AUTOSAR XML (schema 00046)
package /ComponentTypes
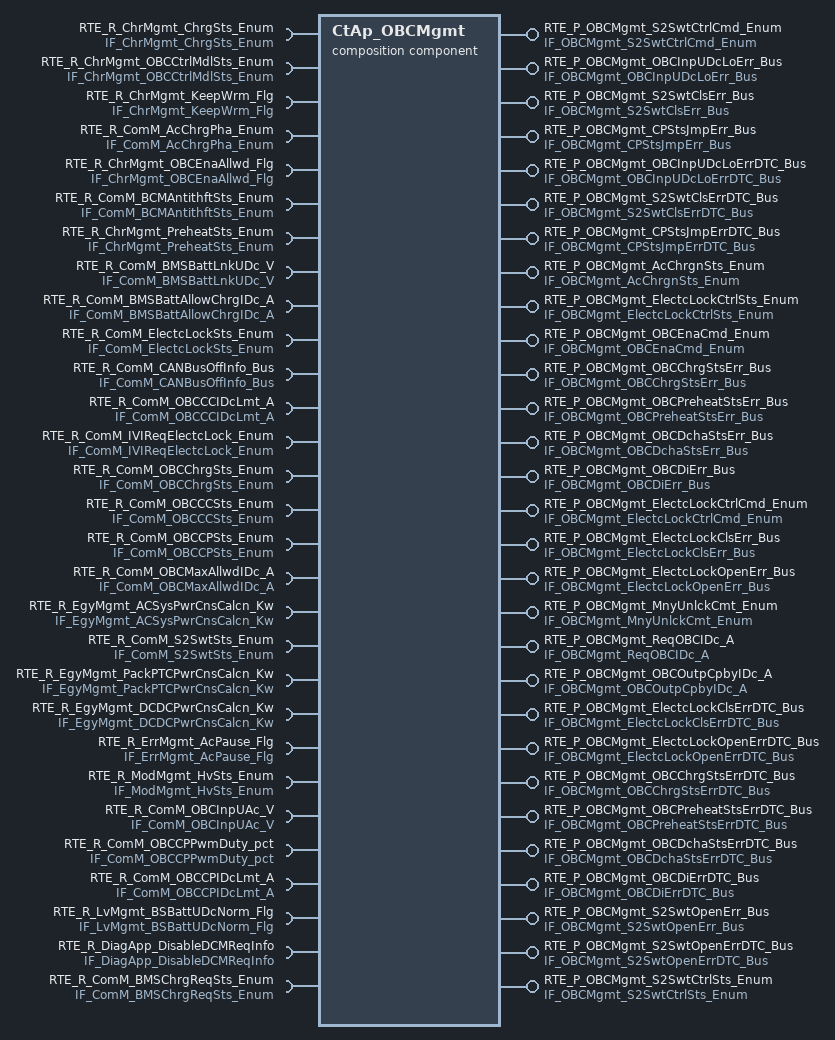
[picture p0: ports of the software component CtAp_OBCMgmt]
  composition sw component type CtAp_OBCMgmt
    26 x provide port:
      RTE_P_OBCMgmt_S2SwtCtrlCmd_Enum: nonqueued-sender-com-spec{data-element=tec_OBCMgmt_S2SwtCtrlCmd_Enum, init-value=0}, provided-interface=IF_OBCMgmt_S2SwtCtrlCmd_Enum
      RTE_P_OBCMgmt_OBCInpUDcLoErr_Bus: nonqueued-sender-com-spec{data-element=tec_OBCMgmt_OBCInpUDcLoErr_Bus, init-value=fields=[OBCMgmt_MonStatOBCInpUDcLoErr:0, OBCMgmt_MonResOBCInpUDcLoErr:0, OBCMgmt_ErrStatOBCInpUDcLoErr:0, OBCMgmt_ErrResOBCInpUDcLoErr:0]}, provided-interface=IF_OBCMgmt_OBCInpUDcLoErr_Bus
      RTE_P_OBCMgmt_S2SwtClsErr_Bus: nonqueued-sender-com-spec{data-element=tec_OBCMgmt_S2SwtClsErr_Bus, init-value=fields=[OBCMgmt_MonStatS2SwtClsErr:0, OBCMgmt_MonResS2SwtClsErr:0, OBCMgmt_ErrStatS2SwtClsErr:0, OBCMgmt_ErrResS2SwtClsErr:0]}, provided-interface=IF_OBCMgmt_S2SwtClsErr_Bus
      RTE_P_OBCMgmt_CPStsJmpErr_Bus: nonqueued-sender-com-spec{data-element=tec_OBCMgmt_CPStsJmpErr_Bus, init-value=fields=[OBCMgmt_MonStatCPStsJmpErr:0, OBCMgmt_MonResCPStsJmpErr:0, OBCMgmt_ErrStatCPStsJmpErr:0, OBCMgmt_ErrResCPStsJmpErr:0]}, provided-interface=IF_OBCMgmt_CPStsJmpErr_Bus
      RTE_P_OBCMgmt_OBCInpUDcLoErrDTC_Bus: nonqueued-sender-com-spec{data-element=tec_OBCMgmt_OBCInpUDcLoErrDTC_Bus, init-value=fields=[OBCMgmt_MonStatOBCInpUDcLoErrDTC:0, OBCMgmt_MonResOBCInpUDcLoErrDTC:0, OBCMgmt_ErrStatOBCInpUDcLoErrDTC:0, OBCMgmt_ErrResOBCInpUDcLoErrDTC:0]}, provided-interface=IF_OBCMgmt_OBCInpUDcLoErrDTC_Bus
      RTE_P_OBCMgmt_S2SwtClsErrDTC_Bus: nonqueued-sender-com-spec{data-element=tec_OBCMgmt_S2SwtClsErrDTC_Bus, init-value=fields=[OBCMgmt_MonStatS2SwtClsErrDTC:0, OBCMgmt_MonResS2SwtClsErrDTC:0, OBCMgmt_ErrStatS2SwtClsErrDTC:0, OBCMgmt_ErrResS2SwtClsErrDTC:0]}, provided-interface=IF_OBCMgmt_S2SwtClsErrDTC_Bus
      RTE_P_OBCMgmt_CPStsJmpErrDTC_Bus: nonqueued-sender-com-spec{data-element=tec_OBCMgmt_CPStsJmpErrDTC_Bus, init-value=fields=[OBCMgmt_MonStatCPStsJmpErrDTC:0, OBCMgmt_MonResCPStsJmpErrDTC:0, OBCMgmt_ErrStatCPStsJmpErrDTC:0, OBCMgmt_ErrResCPStsJmpErrDTC:0]}, provided-interface=IF_OBCMgmt_CPStsJmpErrDTC_Bus
      RTE_P_OBCMgmt_AcChrgnSts_Enum: nonqueued-sender-com-spec{data-element=tec_OBCMgmt_AcChrgnSts_Enum, init-value=0}, provided-interface=IF_OBCMgmt_AcChrgnSts_Enum
      RTE_P_OBCMgmt_ElectcLockCtrlSts_Enum: nonqueued-sender-com-spec{data-element=tec_OBCMgmt_ElectcLockCtrlSts_Enum, init-value=0}, provided-interface=IF_OBCMgmt_ElectcLockCtrlSts_Enum
      RTE_P_OBCMgmt_OBCEnaCmd_Enum: nonqueued-sender-com-spec{data-element=tec_OBCMgmt_OBCEnaCmd_Enum, init-value=0}, provided-interface=IF_OBCMgmt_OBCEnaCmd_Enum
      RTE_P_OBCMgmt_OBCChrgStsErr_Bus: nonqueued-sender-com-spec{data-element=tec_OBCMgmt_OBCChrgStsErr_Bus, init-value=fields=[OBCMgmt_MonStatOBCChrgStsErr:0, OBCMgmt_MonResOBCChrgStsErr:0, OBCMgmt_ErrStatOBCChrgStsErr:0, OBCMgmt_ErrResOBCChrgStsErr:0]}, provided-interface=IF_OBCMgmt_OBCChrgStsErr_Bus
      RTE_P_OBCMgmt_OBCPreheatStsErr_Bus: nonqueued-sender-com-spec{data-element=tec_OBCMgmt_OBCPreheatStsErr_Bus, init-value=fields=[OBCMgmt_MonStatOBCPreheatStsErr:0, OBCMgmt_MonResOBCPreheatStsErr:0, OBCMgmt_ErrStatOBCPreheatStsErr:0, OBCMgmt_ErrResOBCPreheatStsErr:0]}, provided-interface=IF_OBCMgmt_OBCPreheatStsErr_Bus
      RTE_P_OBCMgmt_OBCDchaStsErr_Bus: nonqueued-sender-com-spec{data-element=tec_OBCMgmt_OBCDchaStsErr_Bus, init-value=fields=[OBCMgmt_MonStatOBCDchaStsErr:0, OBCMgmt_MonResOBCDchaStsErr:0, OBCMgmt_ErrStatOBCDchaStsErr:0, OBCMgmt_ErrResOBCDchaStsErr:0]}, provided-interface=IF_OBCMgmt_OBCDchaStsErr_Bus
      RTE_P_OBCMgmt_OBCDiErr_Bus: nonqueued-sender-com-spec{data-element=tec_OBCMgmt_OBCDiErr_Bus, init-value=fields=[OBCMgmt_MonStatOBCDiErr:0, OBCMgmt_MonResOBCDiErr:0, OBCMgmt_ErrStatOBCDiErr:0, OBCMgmt_ErrResOBCDiErr:0]}, provided-interface=IF_OBCMgmt_OBCDiErr_Bus
      RTE_P_OBCMgmt_ElectcLockCtrlCmd_Enum: nonqueued-sender-com-spec{data-element=tec_OBCMgmt_ElectcLockCtrlCmd_Enum, init-value=0}, provided-interface=IF_OBCMgmt_ElectcLockCtrlCmd_Enum
      RTE_P_OBCMgmt_ElectcLockClsErr_Bus: nonqueued-sender-com-spec{data-element=tec_OBCMgmt_ElectcLockClsErr_Bus, init-value=fields=[OBCMgmt_MonStatElectcLockClsErr:0, OBCMgmt_MonResElectcLockClsErr:0, OBCMgmt_ErrStatElectcLockClsErr:0, OBCMgmt_ErrResElectcLockClsErr:0]}, provided-interface=IF_OBCMgmt_ElectcLockClsErr_Bus
      RTE_P_OBCMgmt_ElectcLockOpenErr_Bus: nonqueued-sender-com-spec{data-element=tec_OBCMgmt_ElectcLockOpenErr_Bus, init-value=fields=[OBCMgmt_MonStatElectcLockOpenErr:0, OBCMgmt_MonResElectcLockOpenErr:0, OBCMgmt_ErrStatElectcLockOpenErr:0, OBCMgmt_ErrResElectcLockOpenErr:0]}, provided-interface=IF_OBCMgmt_ElectcLockOpenErr_Bus
      RTE_P_OBCMgmt_MnyUnlckCmt_Enum: nonqueued-sender-com-spec{data-element=tec_OBCMgmt_MnyUnlckCmt_Enum, init-value=0}, provided-interface=IF_OBCMgmt_MnyUnlckCmt_Enum
      RTE_P_OBCMgmt_ReqOBCIDc_A: nonqueued-sender-com-spec{data-element=tec_OBCMgmt_ReqOBCIDc_A, init-value=0}, provided-interface=IF_OBCMgmt_ReqOBCIDc_A
      RTE_P_OBCMgmt_OBCOutpCpbyIDc_A: nonqueued-sender-com-spec{data-element=tec_OBCMgmt_OBCOutpCpbyIDc_A, init-value=0}, provided-interface=IF_OBCMgmt_OBCOutpCpbyIDc_A
      RTE_P_OBCMgmt_ElectcLockClsErrDTC_Bus: nonqueued-sender-com-spec{data-element=tec_OBCMgmt_ElectcLockClsErrDTC_Bus, init-value=fields=[OBCMgmt_MonStatElectcLockClsErrDTC:0, OBCMgmt_MonResElectcLockClsErrDTC:0, OBCMgmt_ErrStatElectcLockClsErrDTC:0, OBCMgmt_ErrResElectcLockClsErrDTC:0]}, provided-interface=IF_OBCMgmt_ElectcLockClsErrDTC_Bus
      RTE_P_OBCMgmt_ElectcLockOpenErrDTC_Bus: nonqueued-sender-com-spec{data-element=tec_OBCMgmt_ElectcLockOpenErrDTC_Bus, init-value=fields=[OBCMgmt_MonStatElectcLockOpenErrDTC:0, OBCMgmt_MonResElectcLockOpenErrDTC:0, OBCMgmt_ErrStatElectcLockOpenErrDTC:0, OBCMgmt_ErrResElectcLockOpenErrDTC:0]}, provided-interface=IF_OBCMgmt_ElectcLockOpenErrDTC_Bus
      RTE_P_OBCMgmt_OBCChrgStsErrDTC_Bus: nonqueued-sender-com-spec{data-element=tec_OBCMgmt_OBCChrgStsErrDTC_Bus, init-value=fields=[OBCMgmt_MonStatOBCChrgStsErrDTC:0, OBCMgmt_MonResOBCChrgStsErrDTC:0, OBCMgmt_ErrStatOBCChrgStsErrDTC:0, OBCMgmt_ErrResOBCChrgStsErrDTC:0]}, provided-interface=IF_OBCMgmt_OBCChrgStsErrDTC_Bus
      RTE_P_OBCMgmt_OBCPreheatStsErrDTC_Bus: nonqueued-sender-com-spec{data-element=tec_OBCMgmt_OBCPreheatStsErrDTC_Bus, init-value=fields=[OBCMgmt_MonStatOBCPreheatStsErrDTC:0, OBCMgmt_MonResOBCPreheatStsErrDTC:0, OBCMgmt_ErrStatOBCPreheatStsErrDTC:0, OBCMgmt_ErrResOBCPreheatStsErrDTC:0]}, provided-interface=IF_OBCMgmt_OBCPreheatStsErrDTC_Bus
      RTE_P_OBCMgmt_OBCDchaStsErrDTC_Bus: nonqueued-sender-com-spec{data-element=tec_OBCMgmt_OBCDchaStsErrDTC_Bus, init-value=fields=[OBCMgmt_MonStatOBCDchaStsErrDTC:0, OBCMgmt_MonResOBCDchaStsErrDTC:0, OBCMgmt_ErrStatOBCDchaStsErrDTC:0, OBCMgmt_ErrResOBCDchaStsErrDTC:0]}, provided-interface=IF_OBCMgmt_OBCDchaStsErrDTC_Bus
      RTE_P_OBCMgmt_OBCDiErrDTC_Bus: nonqueued-sender-com-spec{data-element=tec_OBCMgmt_OBCDiErrDTC_Bus, init-value=fields=[OBCMgmt_MonStatOBCDiErrDTC:0, OBCMgmt_MonResOBCDiErrDTC:0, OBCMgmt_ErrStatOBCDiErrDTC:0, OBCMgmt_ErrResOBCDiErrDTC:0]}, provided-interface=IF_OBCMgmt_OBCDiErrDTC_Bus
    26 x require port:
      RTE_R_ChrMgmt_ChrgSts_Enum: nonqueued-receiver-com-spec{data-element=tec_ChrMgmt_ChrgSts_Enum, filter=data-filter-type=ALWAYS, init-value=0}, required-interface=IF_ChrMgmt_ChrgSts_Enum
      RTE_R_ChrMgmt_OBCCtrlMdlSts_Enum: nonqueued-receiver-com-spec{data-element=tec_ChrMgmt_OBCCtrlMdlSts_Enum, filter=data-filter-type=ALWAYS, init-value=0}, required-interface=IF_ChrMgmt_OBCCtrlMdlSts_Enum
      RTE_R_ChrMgmt_KeepWrm_Flg: nonqueued-receiver-com-spec{data-element=tec_ChrMgmt_KeepWrm_Flg, filter=data-filter-type=ALWAYS, init-value=0}, required-interface=IF_ChrMgmt_KeepWrm_Flg
      RTE_R_ComM_AcChrgPha_Enum: nonqueued-receiver-com-spec{data-element=tec_ComM_AcChrgPha_Enum, filter=data-filter-type=ALWAYS, init-value=0}, required-interface=IF_ComM_AcChrgPha_Enum
      RTE_R_ChrMgmt_OBCEnaAllwd_Flg: nonqueued-receiver-com-spec{data-element=tec_ChrMgmt_OBCEnaAllwd_Flg, filter=data-filter-type=ALWAYS, init-value=0}, required-interface=IF_ChrMgmt_OBCEnaAllwd_Flg
      RTE_R_ComM_BCMAntithftSts_Enum: nonqueued-receiver-com-spec{data-element=tec_ComM_BCMAntithftSts_Enum, filter=data-filter-type=ALWAYS, init-value=0}, required-interface=IF_ComM_BCMAntithftSts_Enum
      RTE_R_ChrMgmt_PreheatSts_Enum: nonqueued-receiver-com-spec{data-element=tec_ChrMgmt_PreheatSts_Enum, filter=data-filter-type=ALWAYS, init-value=0}, required-interface=IF_ChrMgmt_PreheatSts_Enum
      RTE_R_ComM_BMSBattLnkUDc_V: nonqueued-receiver-com-spec{data-element=tec_ComM_BMSBattLnkUDc_V, filter=data-filter-type=ALWAYS, init-value=0}, required-interface=IF_ComM_BMSBattLnkUDc_V
      RTE_R_ComM_BMSBattAllowChrgIDc_A: nonqueued-receiver-com-spec{data-element=tec_ComM_BMSBattAllowChrgIDc_A, filter=data-filter-type=ALWAYS, init-value=0}, required-interface=IF_ComM_BMSBattAllowChrgIDc_A
      RTE_R_ComM_ElectcLockSts_Enum: nonqueued-receiver-com-spec{data-element=tec_ComM_ElectcLockSts_Enum, filter=data-filter-type=ALWAYS, init-value=0}, required-interface=IF_ComM_ElectcLockSts_Enum
      RTE_R_ComM_CANBusOffInfo_Bus: required-interface=IF_ComM_CANBusOffInfo_Bus
        required-com-specs:
          data-element=tec_ComM_EPTCANBusOffInfo_Bus, filter=data-filter-type=ALWAYS, init-value=fields=[ComM_MonStatEPTCANBusOffInfo:0, ComM_MonResEPTCANBusOffInfo:0, ComM_ErrStatEPTCANBusOffInfo:0, ComM_ErrResEPTCANBusOffInfo:0]
          data-element=tec_ComM_CHCANBusOffInfo_Bus, filter=data-filter-type=ALWAYS, init-value=fields=[ComM_MonStatCHCANBusOffInfo:0, ComM_MonResCHCANBusOffInfo:0, ComM_ErrStatCHCANBusOffInfo:0, ComM_ErrResCHCANBusOffInfo:0]
          data-element=tec_ComM_EPTCANBusOffDTCInfo_Bus, filter=data-filter-type=ALWAYS, init-value=fields=[ComM_MonStatEPTCANBusOffDTCInfo:0, ComM_MonResEPTCANBusOffDTCInfo:0, ComM_ErrStatEPTCANBusOffDTCInfo:0, ComM_ErrResEPTCANBusOffDTCInfo:0]
          data-element=tec_ComM_CHCANBusOffDTCInfo_Bus, filter=data-filter-type=ALWAYS, init-value=fields=[ComM_MonStatCHCANBusOffDTCInfo:0, ComM_MonResCHCANBusOffDTCInfo:0, ComM_ErrStatCHCANBusOffDTCInfo:0, ComM_ErrResCHCANBusOffDTCInfo:0]
          data-element=tec_ComM_DCCANBusOffDTCInfo_Bus, filter=data-filter-type=ALWAYS
          data-element=tec_ComM_DCCANBusOffInfo_Bus, filter=data-filter-type=ALWAYS
      RTE_R_ComM_OBCCCIDcLmt_A: nonqueued-receiver-com-spec{data-element=tec_ComM_OBCCCIDcLmt_A, filter=data-filter-type=ALWAYS, init-value=0}, required-interface=IF_ComM_OBCCCIDcLmt_A
      RTE_R_ComM_IVIReqElectcLock_Enum: nonqueued-receiver-com-spec{data-element=tec_ComM_IVIReqElectcLock_Enum, filter=data-filter-type=ALWAYS, init-value=0}, required-interface=IF_ComM_IVIReqElectcLock_Enum
      RTE_R_ComM_OBCChrgSts_Enum: nonqueued-receiver-com-spec{data-element=tec_ComM_OBCChrgSts_Enum, filter=data-filter-type=ALWAYS, init-value=0}, required-interface=IF_ComM_OBCChrgSts_Enum
      RTE_R_ComM_OBCCCSts_Enum: nonqueued-receiver-com-spec{data-element=tec_ComM_OBCCCSts_Enum, filter=data-filter-type=ALWAYS, init-value=0}, required-interface=IF_ComM_OBCCCSts_Enum
      RTE_R_ComM_OBCCPSts_Enum: nonqueued-receiver-com-spec{data-element=tec_ComM_OBCCPSts_Enum, filter=data-filter-type=ALWAYS, init-value=0}, required-interface=IF_ComM_OBCCPSts_Enum
      RTE_R_ComM_OBCMaxAllwdIDc_A: nonqueued-receiver-com-spec{data-element=tec_ComM_OBCMaxAllwdIDc_A, filter=data-filter-type=ALWAYS, init-value=0}, required-interface=IF_ComM_OBCMaxAllwdIDc_A
      RTE_R_EgyMgmt_ACSysPwrCnsCalcn_Kw: nonqueued-receiver-com-spec{data-element=tec_EgyMgmt_ACSysPwrCnsCalcn_Kw, filter=data-filter-type=ALWAYS, init-value=0}, required-interface=IF_EgyMgmt_ACSysPwrCnsCalcn_Kw
      RTE_R_ComM_S2SwtSts_Enum: nonqueued-receiver-com-spec{data-element=tec_ComM_S2SwtSts_Enum, filter=data-filter-type=ALWAYS, init-value=0}, required-interface=IF_ComM_S2SwtSts_Enum
      RTE_R_EgyMgmt_PackPTCPwrCnsCalcn_Kw: nonqueued-receiver-com-spec{data-element=tec_EgyMgmt_PackPTCPwrCnsCalcn_Kw, filter=data-filter-type=ALWAYS, init-value=0}, required-interface=IF_EgyMgmt_PackPTCPwrCnsCalcn_Kw
      RTE_R_EgyMgmt_DCDCPwrCnsCalcn_Kw: nonqueued-receiver-com-spec{data-element=tec_EgyMgmt_DCDCPwrCnsCalcn_Kw, filter=data-filter-type=ALWAYS, init-value=0}, required-interface=IF_EgyMgmt_DCDCPwrCnsCalcn_Kw
      RTE_R_ErrMgmt_AcPause_Flg: nonqueued-receiver-com-spec{data-element=tec_ErrMgmt_AcPause_Flg, filter=data-filter-type=ALWAYS, init-value=0}, required-interface=IF_ErrMgmt_AcPause_Flg
      RTE_R_ModMgmt_HvSts_Enum: nonqueued-receiver-com-spec{data-element=tec_ModMgmt_HvSts_Enum, filter=data-filter-type=ALWAYS, init-value=0}, required-interface=IF_ModMgmt_HvSts_Enum
      RTE_R_ComM_OBCInpUAc_V: nonqueued-receiver-com-spec{data-element=tec_ComM_OBCInpUAc_V, filter=data-filter-type=ALWAYS, init-value=0}, required-interface=IF_ComM_OBCInpUAc_V
      RTE_R_ComM_OBCCPPwmDuty_pct: nonqueued-receiver-com-spec{data-element=tec_ComM_OBCCPPwmDuty_pct, filter=data-filter-type=ALWAYS, init-value=0}, required-interface=IF_ComM_OBCCPPwmDuty_pct
      RTE_R_ComM_OBCCPIDcLmt_A: nonqueued-receiver-com-spec{data-element=tec_ComM_OBCCPIDcLmt_A, filter=data-filter-type=ALWAYS, init-value=0}, required-interface=IF_ComM_OBCCPIDcLmt_A
    provide port RTE_P_OBCMgmt_S2SwtOpenErr_Bus: nonqueued-sender-com-spec{data-element=tec_OBCMgmt_S2SwtOpenErr_Bus, init-value=fields=[OBCMgmt_MonStatS2SwtOpenErr:0, OBCMgmt_MonResS2SwtOpenErr:0, OBCMgmt_ErrStatS2SwtOpenErr:0, OBCMgmt_ErrResS2SwtOpenErr:0]}, provided-interface=IF_OBCMgmt_S2SwtOpenErr_Bus
    provide port RTE_P_OBCMgmt_S2SwtOpenErrDTC_Bus: nonqueued-sender-com-spec{data-element=tec_OBCMgmt_S2SwtOpenErrDTC_Bus, init-value=fields=[OBCMgmt_MonStatS2SwtOpenErrDTC:0, OBCMgmt_MonResS2SwtOpenErrDTC:0, OBCMgmt_ErrStatS2SwtOpenErrDTC:0, OBCMgmt_ErrResS2SwtOpenErrDTC:0]}, provided-interface=IF_OBCMgmt_S2SwtOpenErrDTC_Bus
    provide port RTE_P_OBCMgmt_S2SwtCtrlSts_Enum: nonqueued-sender-com-spec{data-element=tec_OBCMgmt_S2SwtCtrlSts_Enum, init-value=0}, provided-interface=IF_OBCMgmt_S2SwtCtrlSts_Enum
    require port RTE_R_LvMgmt_BSBattUDcNorm_Flg: nonqueued-receiver-com-spec{data-element=tec_LvMgmt_BSBattUDcNorm_Flg, filter=data-filter-type=ALWAYS, init-value=0}, required-interface=IF_LvMgmt_BSBattUDcNorm_Flg
    require port RTE_R_DiagApp_DisableDCMReqInfo: nonqueued-receiver-com-spec{data-element=tec_DiagApp_DisableDCMReqInfo, filter=data-filter-type=ALWAYS, init-value=0}, required-interface=IF_DiagApp_DisableDCMReqInfo
    require port RTE_R_ComM_BMSChrgReqSts_Enum: nonqueued-receiver-com-spec{data-element=tec_ComM_BMSChrgReqSts_Enum, filter=data-filter-type=ALWAYS, init-value=0}, required-interface=IF_ComM_BMSChrgReqSts_Enum
    4 x component:
      CtAp_S2Mgmt: type=CtAp_S2Mgmt
      CtAp_OBCStsMgmt: type=CtAp_OBCStsMgmt
      CtAp_EmMgmt: type=CtAp_EmMgmt
      CtAp_ACParMgmt: type=CtAp_ACParMgmt
    delegate CtAp_S2Mgmt.RTE_R_ComM_CANBusOffInfo_Bus <-> outer port RTE_R_ComM_CANBusOffInfo_Bus
    delegate CtAp_S2Mgmt.RTE_P_OBCMgmt_S2SwtCtrlCmd_Enum <-> outer port RTE_P_OBCMgmt_S2SwtCtrlCmd_Enum
    delegate CtAp_ACParMgmt.RTE_R_EgyMgmt_PackPTCPwrCnsCalcn_Kw <-> outer port RTE_R_EgyMgmt_PackPTCPwrCnsCalcn_Kw
    delegate CtAp_ACParMgmt.RTE_R_EgyMgmt_DCDCPwrCnsCalcn_Kw <-> outer port RTE_R_EgyMgmt_DCDCPwrCnsCalcn_Kw
    delegate CtAp_OBCStsMgmt.RTE_P_OBCMgmt_OBCDiErrDTC_Bus <-> outer port RTE_P_OBCMgmt_OBCDiErrDTC_Bus
    delegate CtAp_OBCStsMgmt.RTE_R_ChrMgmt_KeepWrm_Flg <-> outer port RTE_R_ChrMgmt_KeepWrm_Flg
    delegate CtAp_ACParMgmt.RTE_R_ErrMgmt_AcPause_Flg <-> outer port RTE_R_ErrMgmt_AcPause_Flg
    delegate CtAp_S2Mgmt.RTE_P_OBCMgmt_S2SwtClsErrDTC_Bus <-> outer port RTE_P_OBCMgmt_S2SwtClsErrDTC_Bus
    delegate CtAp_EmMgmt.RTE_P_OBCMgmt_ElectcLockOpenErrDTC_Bus <-> outer port RTE_P_OBCMgmt_ElectcLockOpenErrDTC_Bus
    delegate CtAp_S2Mgmt.RTE_R_ComM_S2SwtSts_Enum <-> outer port RTE_R_ComM_S2SwtSts_Enum
    delegate CtAp_OBCStsMgmt.RTE_P_OBCMgmt_OBCDchaStsErrDTC_Bus <-> outer port RTE_P_OBCMgmt_OBCDchaStsErrDTC_Bus
    delegate CtAp_S2Mgmt.RTE_P_OBCMgmt_OBCInpUDcLoErrDTC_Bus <-> outer port RTE_P_OBCMgmt_OBCInpUDcLoErrDTC_Bus
    delegate CtAp_EmMgmt.RTE_P_OBCMgmt_ElectcLockOpenErr_Bus <-> outer port RTE_P_OBCMgmt_ElectcLockOpenErr_Bus
    delegate CtAp_S2Mgmt.RTE_R_ChrMgmt_PreheatSts_Enum <-> outer port RTE_R_ChrMgmt_PreheatSts_Enum
    delegate CtAp_ACParMgmt.RTE_R_ModMgmt_HvSts_Enum <-> outer port RTE_R_ModMgmt_HvSts_Enum
    delegate CtAp_S2Mgmt.RTE_P_OBCMgmt_CPStsJmpErr_Bus <-> outer port RTE_P_OBCMgmt_CPStsJmpErr_Bus
    delegate CtAp_EmMgmt.RTE_P_OBCMgmt_ElectcLockClsErrDTC_Bus <-> outer port RTE_P_OBCMgmt_ElectcLockClsErrDTC_Bus
    delegate CtAp_EmMgmt.RTE_P_OBCMgmt_ElectcLockCtrlCmd_Enum <-> outer port RTE_P_OBCMgmt_ElectcLockCtrlCmd_Enum
    delegate CtAp_EmMgmt.RTE_P_OBCMgmt_ElectcLockClsErr_Bus <-> outer port RTE_P_OBCMgmt_ElectcLockClsErr_Bus
    delegate CtAp_OBCStsMgmt.RTE_P_OBCMgmt_OBCPreheatStsErr_Bus <-> outer port RTE_P_OBCMgmt_OBCPreheatStsErr_Bus
    delegate CtAp_OBCStsMgmt.RTE_R_ComM_OBCCPPwmDuty_pct <-> outer port RTE_R_ComM_OBCCPPwmDuty_pct
    delegate CtAp_OBCStsMgmt.RTE_P_OBCMgmt_OBCChrgStsErr_Bus <-> outer port RTE_P_OBCMgmt_OBCChrgStsErr_Bus
    delegate CtAp_ACParMgmt.RTE_P_OBCMgmt_ReqOBCIDc_A <-> outer port RTE_P_OBCMgmt_ReqOBCIDc_A
    delegate CtAp_EmMgmt.RTE_R_ComM_IVIReqElectcLock_Enum <-> outer port RTE_R_ComM_IVIReqElectcLock_Enum
    delegate CtAp_S2Mgmt.RTE_P_OBCMgmt_CPStsJmpErrDTC_Bus <-> outer port RTE_P_OBCMgmt_CPStsJmpErrDTC_Bus
    delegate CtAp_EmMgmt.RTE_P_OBCMgmt_ElectcLockCtrlSts_Enum <-> outer port RTE_P_OBCMgmt_ElectcLockCtrlSts_Enum
    delegate CtAp_OBCStsMgmt.RTE_R_ChrMgmt_OBCEnaAllwd_Flg <-> outer port RTE_R_ChrMgmt_OBCEnaAllwd_Flg
    delegate CtAp_EmMgmt.RTE_R_ComM_OBCCCSts_Enum <-> outer port RTE_R_ComM_OBCCCSts_Enum
    delegate CtAp_EmMgmt.RTE_R_ComM_ElectcLockSts_Enum <-> outer port RTE_R_ComM_ElectcLockSts_Enum
    delegate CtAp_EmMgmt.RTE_R_ComM_OBCCPSts_Enum <-> outer port RTE_R_ComM_OBCCPSts_Enum
    delegate CtAp_OBCStsMgmt.RTE_P_OBCMgmt_OBCDchaStsErr_Bus <-> outer port RTE_P_OBCMgmt_OBCDchaStsErr_Bus
    delegate CtAp_ACParMgmt.RTE_R_ComM_BMSBattLnkUDc_V <-> outer port RTE_R_ComM_BMSBattLnkUDc_V
    delegate CtAp_OBCStsMgmt.RTE_P_OBCMgmt_OBCDiErr_Bus <-> outer port RTE_P_OBCMgmt_OBCDiErr_Bus
    delegate CtAp_OBCStsMgmt.RTE_P_OBCMgmt_OBCChrgStsErrDTC_Bus <-> outer port RTE_P_OBCMgmt_OBCChrgStsErrDTC_Bus
    delegate CtAp_S2Mgmt.RTE_R_ComM_OBCInpUAc_V <-> outer port RTE_R_ComM_OBCInpUAc_V
    delegate CtAp_ACParMgmt.RTE_R_ComM_BMSBattAllowChrgIDc_A <-> outer port RTE_R_ComM_BMSBattAllowChrgIDc_A
    delegate CtAp_OBCStsMgmt.RTE_P_OBCMgmt_OBCPreheatStsErrDTC_Bus <-> outer port RTE_P_OBCMgmt_OBCPreheatStsErrDTC_Bus
    delegate CtAp_EmMgmt.RTE_P_OBCMgmt_MnyUnlckCmt_Enum <-> outer port RTE_P_OBCMgmt_MnyUnlckCmt_Enum
    delegate CtAp_EmMgmt.RTE_R_ComM_OBCChrgSts_Enum <-> outer port RTE_R_ComM_OBCChrgSts_Enum
    delegate CtAp_ACParMgmt.RTE_R_EgyMgmt_ACSysPwrCnsCalcn_Kw <-> outer port RTE_R_EgyMgmt_ACSysPwrCnsCalcn_Kw
    delegate CtAp_ACParMgmt.RTE_R_ComM_OBCCCIDcLmt_A <-> outer port RTE_R_ComM_OBCCCIDcLmt_A
    delegate CtAp_S2Mgmt.RTE_P_OBCMgmt_S2SwtClsErr_Bus <-> outer port RTE_P_OBCMgmt_S2SwtClsErr_Bus
    delegate CtAp_OBCStsMgmt.RTE_R_ChrMgmt_OBCCtrlMdlSts_Enum <-> outer port RTE_R_ChrMgmt_OBCCtrlMdlSts_Enum
    delegate CtAp_S2Mgmt.RTE_P_OBCMgmt_S2SwtOpenErrDTC_Bus <-> outer port RTE_P_OBCMgmt_S2SwtOpenErrDTC_Bus
    delegate CtAp_ACParMgmt.RTE_R_ComM_OBCCPIDcLmt_A <-> outer port RTE_R_ComM_OBCCPIDcLmt_A
    delegate CtAp_S2Mgmt.RTE_P_OBCMgmt_S2SwtOpenErr_Bus <-> outer port RTE_P_OBCMgmt_S2SwtOpenErr_Bus
    delegate CtAp_OBCStsMgmt.RTE_R_ChrMgmt_ChrgSts_Enum <-> outer port RTE_R_ChrMgmt_ChrgSts_Enum
    delegate CtAp_EmMgmt.RTE_R_ComM_BCMAntithftSts_Enum <-> outer port RTE_R_ComM_BCMAntithftSts_Enum
    delegate CtAp_ACParMgmt.RTE_R_ComM_OBCMaxAllwdIDc_A <-> outer port RTE_R_ComM_OBCMaxAllwdIDc_A
    delegate CtAp_S2Mgmt.RTE_P_OBCMgmt_OBCInpUDcLoErr_Bus <-> outer port RTE_P_OBCMgmt_OBCInpUDcLoErr_Bus
    delegate CtAp_OBCStsMgmt.RTE_P_OBCMgmt_OBCEnaCmd_Enum <-> outer port RTE_P_OBCMgmt_OBCEnaCmd_Enum
    delegate CtAp_ACParMgmt.RTE_P_OBCMgmt_OBCOutpCpbyIDc_A <-> outer port RTE_P_OBCMgmt_OBCOutpCpbyIDc_A
    delegate CtAp_ACParMgmt.RTE_R_ComM_AcChrgPha_Enum <-> outer port RTE_R_ComM_AcChrgPha_Enum
    delegate CtAp_S2Mgmt.RTE_R_ComM_OBCCPSts_Enum <-> outer port RTE_R_ComM_OBCCPSts_Enum
    delegate CtAp_OBCStsMgmt.RTE_P_OBCMgmt_AcChrgnSts_Enum <-> outer port RTE_P_OBCMgmt_AcChrgnSts_Enum
    delegate CtAp_OBCStsMgmt.RTE_R_ChrMgmt_PreheatSts_Enum <-> outer port RTE_R_ChrMgmt_PreheatSts_Enum
    delegate CtAp_OBCStsMgmt.RTE_R_ComM_OBCCPSts_Enum <-> outer port RTE_R_ComM_OBCCPSts_Enum
    delegate CtAp_OBCStsMgmt.RTE_R_ComM_OBCChrgSts_Enum <-> outer port RTE_R_ComM_OBCChrgSts_Enum
    connect CtAp_EmMgmt.RTE_P_OBCMgmt_ElectcLockCtrlSts_Enum -> CtAp_OBCStsMgmt.RTE_R_OBCMgmt_ElectcLockCtrlSts_Enum
    delegate CtAp_OBCStsMgmt.RTE_R_ComM_CANBusOffInfo_Bus <-> outer port RTE_R_ComM_CANBusOffInfo_Bus
    delegate CtAp_S2Mgmt.RTE_P_OBCMgmt_S2SwtCtrlSts_Enum <-> outer port RTE_P_OBCMgmt_S2SwtCtrlSts_Enum
    connect CtAp_S2Mgmt.RTE_P_OBCMgmt_S2SwtCtrlSts_Enum -> CtAp_OBCStsMgmt.RTE_R_OBCMgmt_S2SwtCtrlSts_Enum
    delegate CtAp_EmMgmt.RTE_R_ChrMgmt_ChrgSts_Enum <-> outer port RTE_R_ChrMgmt_ChrgSts_Enum
    delegate CtAp_EmMgmt.RTE_R_ComM_CANBusOffInfo_Bus <-> outer port RTE_R_ComM_CANBusOffInfo_Bus
    connect CtAp_OBCStsMgmt.RTE_P_OBCMgmt_AcChrgnSts_Enum -> CtAp_EmMgmt.RTE_R_OBCMgmt_AcChrgnSts_Enum
    delegate CtAp_ACParMgmt.RTE_R_ComM_OBCInpUAc_V <-> outer port RTE_R_ComM_OBCInpUAc_V
    connect CtAp_OBCStsMgmt.RTE_P_OBCMgmt_AcChrgnSts_Enum -> CtAp_ACParMgmt.RTE_R_OBCMgmt_AcChrgnSts_Enum
    delegate CtAp_ACParMgmt.RTE_R_LvMgmt_BSBattUDcNorm_Flg <-> outer port RTE_R_LvMgmt_BSBattUDcNorm_Flg
    delegate CtAp_OBCStsMgmt.RTE_R_LvMgmt_BSBattUDcNorm_Flg <-> outer port RTE_R_LvMgmt_BSBattUDcNorm_Flg
    delegate CtAp_EmMgmt.RTE_R_LvMgmt_BSBattUDcNorm_Flg <-> outer port RTE_R_LvMgmt_BSBattUDcNorm_Flg
    delegate CtAp_S2Mgmt.RTE_R_LvMgmt_BSBattUDcNorm_Flg <-> outer port RTE_R_LvMgmt_BSBattUDcNorm_Flg
    connect CtAp_EmMgmt.RTE_P_OBCMgmt_ElectcLockCtrlSts_Enum -> CtAp_S2Mgmt.RTE_R_OBCMgmt_ElectcLockCtrlSts_Enum
    connect CtAp_OBCStsMgmt.RTE_P_OBCMgmt_AcChrgnSts_Enum -> CtAp_S2Mgmt.RTE_R_OBCMgmt_AcChrgnSts_Enum
    delegate CtAp_S2Mgmt.RTE_R_DiagApp_DisableDCMReqInfo <-> outer port RTE_R_DiagApp_DisableDCMReqInfo
    delegate CtAp_OBCStsMgmt.RTE_R_DiagApp_DisableDCMReqInfo <-> outer port RTE_R_DiagApp_DisableDCMReqInfo
    delegate CtAp_EmMgmt.RTE_R_DiagApp_DisableDCMReqInfo <-> outer port RTE_R_DiagApp_DisableDCMReqInfo
    delegate CtAp_ACParMgmt.RTE_R_ComM_BMSChrgReqSts_Enum <-> outer port RTE_R_ComM_BMSChrgReqSts_Enum
    delegate CtAp_ACParMgmt.RTE_R_ChrMgmt_PreheatSts_Enum <-> outer port RTE_R_ChrMgmt_PreheatSts_Enum
